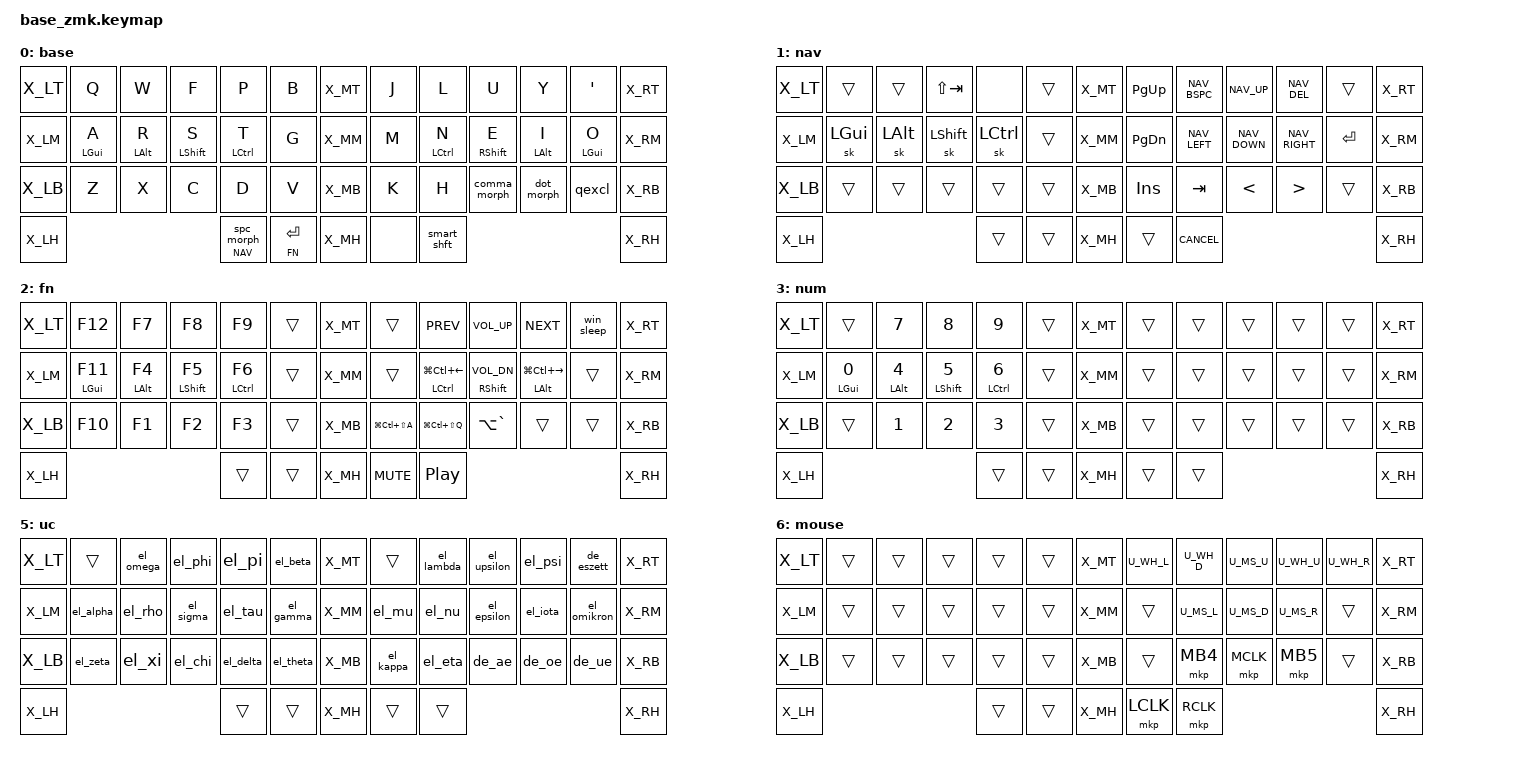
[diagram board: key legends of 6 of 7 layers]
#include <behaviors.dtsi>
#include <behaviors/num_word.dtsi> // requires auto-layer module
#include <dt-bindings/zmk/keys.h>
#if CONFIG_WIRELESS
    #include <dt-bindings/zmk/bt.h>
    #define _BT_SEL_KEYS_ &bt BT_SEL 0 &bt BT_SEL 1 &bt BT_SEL 2 &bt BT_SEL 3 &bt BT_CLR
#else
    #define _BT_SEL_KEYS_ &trans &trans &trans &trans &trans
#endif

#include "zmk-helpers/helper.h"
#include "zmk-helpers/unicode-chars/greek.dtsi"
#include "zmk-helpers/unicode-chars/german.dtsi"

#define DEF 0
#define NAV 1
#define FN 2
#define NUM 3
#define SYS 4
#define UC 5
#define MOUSE 6

#include "combos.dtsi"  // requires layer aliases
#include "mouse.dtsi"
#include "extra_keys.h"

#define XXX &none
#define ___ &trans

/* Global settings */

#define QUICK_TAP_MS 175

&sk {  // sticky-key config
    release-after-ms = <900>;  // release after 0.6s
    quick-release;             // no double capitalization when rolling keys
};

&sl {  // sticky-layer config
    ignore-modifiers;          // allow chording sticky mods & layers
};

&lt {  // layer-tap config
    flavor = "balanced";
    tapping-term-ms = <200>;
    quick-tap-ms = <QUICK_TAP_MS>;
};

/* Homerow mods */

#define KEYS_L LT0 LT1 LT2 LT3 LT4 LM0 LM1 LM2 LM3 LM4 LB0 LB1 LB2 LB3 LB4  // left hand
#define KEYS_R RT0 RT1 RT2 RT3 RT4 RM0 RM1 RM2 RM3 RM4 RB0 RB1 RB2 RB3 RB4  // right hand
#define THUMBS LH1 LH0 RH0 RH1                                      // thumbs

/ {
    behaviors {
        /* Homerow mods */

        hml: homerow_mods_left {
            compatible = "zmk,behavior-hold-tap";
            label = "HOMEROW_MODS_LEFT";
            #binding-cells = <2>;
            flavor = "balanced";
            tapping-term-ms = <280>;
            quick-tap-ms = <QUICK_TAP_MS>;
            require-prior-idle-ms = <150>;
            bindings = <&kp>, <&kp>;
            hold-trigger-key-positions = <KEYS_R THUMBS>;  // right-hand keys and thumbs
            hold-trigger-on-release;
        };

        hmr: homerow_mods_right {
            compatible = "zmk,behavior-hold-tap";
            label = "HOMEROW_MODS_RIGHT";
            #binding-cells = <2>;
            flavor = "balanced";
            tapping-term-ms = <280>;
            quick-tap-ms = <QUICK_TAP_MS>;
            require-prior-idle-ms = <150>;
            bindings = <&kp>, <&kp>;
            hold-trigger-key-positions = <KEYS_L THUMBS>;  // left-hand keys and thumbs
            hold-trigger-on-release;
        };

        // used for HRM-combo
        hml_repeat: homerow_mods_left_repeat {
            compatible = "zmk,behavior-hold-tap";
            label = "HOMEROW_MODS_LEFT_REPEAT";
            #binding-cells = <2>;
            flavor = "balanced";
            tapping-term-ms = <280>;
            quick-tap-ms = <QUICK_TAP_MS>;
            require-prior-idle-ms = <150>;
            bindings = <&kp>, <&key_repeat>;
            hold-trigger-key-positions = <KEYS_R THUMBS>;
            hold-trigger-on-release;
        };

        hmr_lpar_lt: homerow_mods_right_lpar_lt {
            compatible = "zmk,behavior-hold-tap";
            label = "HOMEROW_MODS_RIGHT_LPAR_LT";
            #binding-cells = <2>;
            flavor = "balanced";
            tapping-term-ms = <280>;
            quick-tap-ms = <QUICK_TAP_MS>;
            require-prior-idle-ms = <150>;
            bindings = <&kp>, <&lpar_lt>;
            hold-trigger-key-positions = <KEYS_L THUMBS>;
            hold-trigger-on-release;
        };

        hmr_rpar_gt: homerow_mods_right_rpar_gt {
            compatible = "zmk,behavior-hold-tap";
            label = "HOMEROW_MODS_RIGHT_RPAR_GT";
            #binding-cells = <2>;
            flavor = "balanced";
            tapping-term-ms = <280>;
            quick-tap-ms = <QUICK_TAP_MS>;
            require-prior-idle-ms = <150>;
            bindings = <&kp>, <&rpar_gt>;
            hold-trigger-key-positions = <KEYS_L THUMBS>;
            hold-trigger-on-release;
        };

        /* Nav cluster */

        // long-tap action on hold, short-tap action on all interrupts
        mt: mod_tap {
            compatible = "zmk,behavior-hold-tap";
            #binding-cells = <2>;
            flavor = "tap-preferred";
            tapping-term-ms = <220>;
            quick-tap-ms = <220>;
            hold-trigger-key-positions = <0>;
            bindings = <&kp>, <&kp>;
        };

        mt_home: mod_tap_home {
            compatible = "zmk,behavior-hold-tap";
            #binding-cells = <2>;
            flavor = "tap-preferred";
            tapping-term-ms = <220>;
            quick-tap-ms = <220>;
            hold-trigger-key-positions = <0>;
            bindings = <&masked_home>, <&kp>;
        };

        mt_end: mod_tap_end {
            compatible = "zmk,behavior-hold-tap";
            #binding-cells = <2>;
            flavor = "tap-preferred";
            tapping-term-ms = <220>;
            quick-tap-ms = <220>;
            hold-trigger-key-positions = <0>;
            bindings = <&masked_end>, <&kp>;
        };

        // mask CTRL when holding left/right to avoid accidental jumps to beginning/end of document
        masked_home: masked_home {
            compatible = "zmk,behavior-mod-morph";
            #binding-cells = <0>;
            bindings = <&kp HOME>, <&kp HOME>;
            mods = <(MOD_LCTL)>;
        };

        masked_end: masked_end {
            compatible = "zmk,behavior-mod-morph";
            #binding-cells = <0>;
            bindings = <&kp END>, <&kp END>;
            mods = <(MOD_LCTL)>;
        };

        /* Caps-word, num-word and smart-mouse */

        // tap: sticky-shift | shift + tap/ double-tap: caps-word | hold: shift
        smart_shft: smart_shift {
            compatible = "zmk,behavior-mod-morph";
            #binding-cells = <0>;
            bindings = <&sk LSHFT>, <&caps_word>;
            mods = <(MOD_LSFT)>;
        };

        // tap: num-word | double-tap: sticky num-layer | hold: num-layer
        smart_num: smart_num {
            compatible = "zmk,behavior-hold-tap";
            label = "SMART_NUM";
            #binding-cells = <2>;
            flavor = "balanced";
            tapping-term-ms = <200>;
            quick-tap-ms = <QUICK_TAP_MS>;
            bindings = <&mo>, <&num_dance>;
        };

        num_dance: num_word_dance {
            compatible = "zmk,behavior-tap-dance";
            label = "NUM_WORD_DANCE";
            #binding-cells = <0>;
            tapping-term-ms = <200>;
            bindings = <&num_word NUM>, <&sl NUM>;
        };

        // smart-mouse, requires PR #1366
        smart_mouse: smart_mouse {
            compatible = "zmk,behavior-tri-state";
            label = "SMART_MOUSE";
            #binding-cells = <0>;
            bindings = <&tog MOUSE>, <&none>, <&tog MOUSE>;
            ignored-key-positions = <LT1 LT3 RT0 RT1 RT2 RT3 RT4 RM1 RM2 RM3 RB1 RB2 RB3 RH0 RH1>;
            ignored-layers = <MOUSE>;
        };

        /* Custom behaviors */

        // Alt+Tab swapper, requires PR #1366
        swapper: swapper {
            compatible = "zmk,behavior-tri-state";
            label = "SWAPPER";
            #binding-cells = <0>;
            bindings = <&kt LALT>, <&kp TAB>, <&kt LALT>;
            ignored-key-positions = <LT2>;
        };

        // Sticky layer + sticky shift (workaround for issue #1421)
        sls: sticky_layer_shift {
            compatible = "zmk,behavior-sticky-key";
            label = "STICKY_LAYER_SHIFT";
            #binding-cells = <1>;
            release-after-ms = <1000>;
            bindings = <&uc_shift>;
            ignore-modifiers;
        };

        // tap: comma | shift + tap: semicolon | ctrl + shift + tap: <
        comma_morph: comma_morph {
            compatible = "zmk,behavior-mod-morph";
            label = "COMMA_MORPH";
            #binding-cells = <0>;
            bindings = <&kp COMMA>, <&comma_inner_morph>;
            mods = <(MOD_LSFT|MOD_RSFT)>;
        };

        comma_inner_morph: comma_inner_morph {
            compatible = "zmk,behavior-mod-morph";
            label = "COMMA_INNER_MORPH";
            #binding-cells = <0>;
            bindings = <&kp SEMICOLON>, <&kp LESS_THAN>;
            mods = <(MOD_LCTL|MOD_RCTL)>;
        };

        // tap: dot | shift + tap: colon | ctrl + shift + tap: >
        dot_morph: dot_morph {
            compatible = "zmk,behavior-mod-morph";
            label = "DOT_MORPH";
            #binding-cells = <0>;
            bindings = <&kp DOT>, <&dot_inner_morph>;
            mods = <(MOD_LSFT|MOD_RSFT)>;
        };

        dot_inner_morph: dot_inner_morph {
            compatible = "zmk,behavior-mod-morph";
            label = "DOT_INNER_MORPH";
            #binding-cells = <0>;
            bindings = <&kp COLON>, <&kp GREATER_THAN>;
            mods = <(MOD_LCTL|MOD_RCTL)>;
        };

        // tap: qmark | shift + tap: excl
        qexcl: question_exclamation {
            compatible = "zmk,behavior-mod-morph";
            label = "QUESTION_EXCLAMATION";
            #binding-cells = <0>;
            bindings = <&kp QMARK>, <&kp EXCL>;
            mods = <(MOD_LSFT|MOD_RSFT)>;
        };

        // tap: left/right parenthesis | shft + tap: less-than/greater-than
        lpar_lt: left_parenthesis_less_than {
            compatible = "zmk,behavior-mod-morph";
            label = "LEFT_PARENTHESIS_LESS_THAN";
            #binding-cells = <0>;
            bindings = <&kp LPAR>, <&kp LT>;
            mods = <(MOD_LSFT|MOD_RSFT)>;
        };

        rpar_gt: right_parenthesis_greater_than {
            compatible = "zmk,behavior-mod-morph";
            label = "RIGHT_PARENTHESIS_GREATER_THAN";
            #binding-cells = <0>;
            bindings = <&kp RPAR>, <&kp GT>;
            mods = <(MOD_LSFT|MOD_RSFT)>;
        };

        // tap: space | shift + tap: dot -> space -> sticky shift | hold: activate layer
        lt_spc: layer_tap_space {
            compatible = "zmk,behavior-hold-tap";
            label = "LAYER_TAP_SPACE";
            #binding-cells = <2>;
            flavor = "balanced";
            tapping-term-ms = <200>;
            quick-tap-ms = <QUICK_TAP_MS>;
            bindings = <&mo>, <&spc_morph>;
        };

        spc_morph: space_morph {
            compatible = "zmk,behavior-mod-morph";
            label = "SPACE_MORPH";
            #binding-cells = <0>;
            bindings = <&kp SPACE>, <&dot_spc>;
            mods = <(MOD_LSFT|MOD_RSFT)>;
        };

        // tap: backspace | lshft + tap: delete | rshft + tap: shift-delete
        bs_del: backspace_delete {
            compatible = "zmk,behavior-mod-morph";
            label = "BACKSPACE_DELETE";
            #binding-cells = <0>;
            bindings = <&kp BSPC>, <&kp DEL>;
            mods = <(MOD_LSFT|MOD_RSFT)>;
            keep-mods = <MOD_RSFT>;
        };

        // tap: copy | double-tap: cut
        copy_cut: copy_cut {
            compatible = "zmk,behavior-tap-dance";
            label = "COPY_CUT";
            #binding-cells = <0>;
            tapping-term-ms = <200>;
            bindings = <&kp LC(INS)>, <&kp LC(X)>;
        };
    };

    macros {
        // Sticky layer + sticky shift (workaround for issue #1421)
        uc_shift: unicode_shift {
            compatible = "zmk,behavior-macro";
            label = "UNICODE_SHIFT";
            #binding-cells = <0>;
            wait-ms = <0>;
            tap-ms = <1>;
            bindings = <&macro_press &mo UC &kp LSHFT>,
                       <&macro_pause_for_release>,
                       <&macro_release &mo UC &kp LSHFT>;
        };

        // tap: space | shift + tap: dot -> space -> sticky shift | hold: activate layer
        dot_spc: dot_space {
            compatible = "zmk,behavior-macro";
            label = "DOT_SPACE";
            #binding-cells = <0>;
            wait-ms = <0>;
            tap-ms = <5>;
            bindings = <&kp DOT &kp SPACE &sk LSHFT>;
        };

        // Windows sleep key
        win_sleep: windows_sleep {
            compatible = "zmk,behavior-macro";
            label = "WINDOWS_SLEEP";
            #binding-cells = <0>;
            wait-ms = <500>;
            tap-ms = <50>;
            bindings = <&kp LG(X) &kp U &kp S>;
        };
    };
};

// misc aliases
#define CANCEL      &kp K_CANCEL             // cancel caps-word, num-word and smart-mouse
#define DSK_PREV    &hmr LCTRL LG(LC(LEFT))   // previous desktop
#define DSK_NEXT    &hmr LALT LG(LC(RIGHT)) // next     desktop
#define PIN_WIN     &kp LG(LC(LS(Q)))        // pin window across desktops
#define PIN_APP     &kp LG(LC(LS(A)))        // pin application across desktops
#define DSK_MGR     &kp LA(GRAVE)            // desktop manager
#define VOL_DOWN    &hmr RSHFT C_VOL_DN

/* Keymap */

// ZMK_CONDITIONAL_LAYER(sys, FN NUM, SYS)  // FN + NUM --> SYS

ZMK_LAYER(base,
//╭──────╮ ╭─────────────┬─────────────┬─────────────┬─────────────┬─────────────╮ ╭──────╮ ╭─────────────┬─────────────┬─────────────┬─────────────┬─────────────╮ ╭──────╮
    X_LT     &kp Q         &kp W         &kp F         &kp P         &kp B           X_MT     &kp J         &kp L         &kp U         &kp Y         &kp SQT         X_RT
//├──────┤ ├─────────────┼─────────────┼─────────────┼─────────────┼─────────────┤ ├──────┤ ├─────────────┼─────────────┼─────────────┼─────────────┼─────────────┤ ├──────┤
    X_LM     &hml LGUI A   &hml LALT R   &hml LSHFT S  &hml LCTRL T  &kp G           X_MM     &kp M         &hmr LCTRL N  &hmr RSHFT E  &hmr LALT I   &hmr LGUI O     X_RM
//├──────┤ ├─────────────┼─────────────┼─────────────┼─────────────┼─────────────┤ ├──────┤ ├─────────────┼─────────────┼─────────────┼─────────────┼─────────────┤ ├──────┤
    X_LB     &kp Z         &kp X         &kp C         &kp D         &kp V           X_MB     &kp K         &kp H         &comma_morph  &dot_morph    &qexcl          X_RB
//├──────┤ ╰─────────────┼─────────────┴─────────────┼─────────────┼─────────────┤ ├──────┤ ├─────────────┼─────────────┼─────────────┴───────────────────────────╯ ├──────┤
    X_LH                                               &lt_spc NAV 0 &lt FN RET      X_MH     &none     &smart_shft                                               X_RH
//╰──────╯                                           ╰─────────────┴─────────────╯ ╰──────╯ ╰─────────────┴─────────────╯                                           ╰──────╯
)

ZMK_LAYER(nav,
//╭──────╮ ╭─────────────┬─────────────┬─────────────┬─────────────┬─────────────╮ ╭──────╮ ╭─────────────┬─────────────┬─────────────┬─────────────┬─────────────╮ ╭──────╮
    X_LT     ___           ___           &kp LS(TAB)   &none         ___             X_MT     &kp PG_UP     NAV_BSPC      NAV_UP        NAV_DEL       ___             X_RT
//├──────┤ ├─────────────┼─────────────┼─────────────┼─────────────┼─────────────┤ ├──────┤ ├─────────────┼─────────────┼─────────────┼─────────────┼─────────────┤ ├──────┤
    X_LM     &sk LGUI      &sk LALT      &sk LSHFT     &sk LCTRL     ___             X_MM     &kp PG_DN     NAV_LEFT      NAV_DOWN      NAV_RIGHT     &kp RET         X_RM
//├──────┤ ├─────────────┼─────────────┼─────────────┼─────────────┼─────────────┤ ├──────┤ ├─────────────┼─────────────┼─────────────┼─────────────┼─────────────┤ ├──────┤
    X_LB     ___           ___           ___           ___           ___             X_MB     &kp INS       &kp TAB       &kp LT        &kp GT        ___             X_RB
//├──────┤ ╰─────────────┼─────────────┴─────────────┼─────────────┼─────────────┤ ├──────┤ ├─────────────┼─────────────┼─────────────┴───────────────────────────╯ ├──────┤
    X_LH                                               ___           ___             X_MH     ___           CANCEL                                                    X_RH
//╰──────╯                                           ╰─────────────┴─────────────╯ ╰──────╯ ╰─────────────┴─────────────╯                                           ╰──────╯
)

ZMK_LAYER(fn,
//╭──────╮ ╭─────────────┬─────────────┬─────────────┬─────────────┬─────────────╮ ╭──────╮ ╭─────────────┬─────────────┬─────────────┬─────────────┬─────────────╮ ╭──────╮
    X_LT     &kp F12       &kp F7        &kp F8        &kp F9        ___             X_MT     ___           &kp C_PREV    &kp C_VOL_UP  &kp C_NEXT    &win_sleep      X_RT
//├──────┤ ├─────────────┼─────────────┼─────────────┼─────────────┼─────────────┤ ├──────┤ ├─────────────┼─────────────┼─────────────┼─────────────┼─────────────┤ ├──────┤
    X_LM     &hml LGUI F11 &hml LALT F4  &hml LSHFT F5 &hml LCTRL F6 ___             X_MM     ___           DSK_PREV      VOL_DOWN      DSK_NEXT      ___             X_RM
//├──────┤ ├─────────────┼─────────────┼─────────────┼─────────────┼─────────────┤ ├──────┤ ├─────────────┼─────────────┼─────────────┼─────────────┼─────────────┤ ├──────┤
    X_LB     &kp F10       &kp F1        &kp F2        &kp F3        ___             X_MB     PIN_APP       PIN_WIN       DSK_MGR       ___           ___             X_RB
//├──────┤ ╰─────────────┼─────────────┴─────────────┼─────────────┼─────────────┤ ├──────┤ ├─────────────┼─────────────┼─────────────┴───────────────────────────╯ ├──────┤
    X_LH                                               ___           ___             X_MH     &kp C_MUTE    &kp C_PP                                                  X_RH
//╰──────╯                                           ╰─────────────┴─────────────╯ ╰──────╯ ╰─────────────┴─────────────╯                                           ╰──────╯
)

ZMK_LAYER(num,
//╭──────╮ ╭─────────────┬─────────────┬─────────────┬─────────────┬─────────────╮ ╭──────╮ ╭─────────────┬─────────────┬─────────────┬─────────────┬─────────────╮ ╭──────╮
    X_LT     ___           &kp N7        &kp N8        &kp N9        ___             X_MT     ___           ___           ___           ___           ___             X_RT
//├──────┤ ├─────────────┼─────────────┼─────────────┼─────────────┼─────────────┤ ├──────┤ ├─────────────┼─────────────┼─────────────┼─────────────┼─────────────┤ ├──────┤
    X_LM     &hml LGUI N0  &hml LALT N4  &hml LSHFT N5 &hml LCTRL N6 ___             X_MM     ___           ___           ___           ___           ___             X_RM
//├──────┤ ├─────────────┼─────────────┼─────────────┼─────────────┼─────────────┤ ├──────┤ ├─────────────┼─────────────┼─────────────┼─────────────┼─────────────┤ ├──────┤
    X_LB     ___           &kp N1        &kp N2        &kp N3        ___             X_MB     ___           ___           ___           ___           ___             X_RB
//├──────┤ ╰─────────────┼─────────────┴─────────────┼─────────────┼─────────────┤ ├──────┤ ├─────────────┼─────────────┼─────────────┴───────────────────────────╯ ├──────┤
    X_LH                                               ___           ___             X_MH     ___           ___                                                       X_RH
//╰──────╯                                           ╰─────────────┴─────────────╯ ╰──────╯ ╰─────────────┴─────────────╯                                           ╰──────╯
)

ZMK_LAYER(sys,
//╭──────╮ ╭─────────────┬─────────────┬─────────────┬─────────────┬─────────────╮ ╭──────╮ ╭─────────────┬─────────────┬─────────────┬─────────────┬─────────────╮ ╭──────╮
    X_LT                                _BT_SEL_KEYS_                                X_MT     ___           ___           ___           ___           ___             X_RT
//├──────┤ ├─────────────┼─────────────┼─────────────┼─────────────┼─────────────┤ ├──────┤ ├─────────────┼─────────────┼─────────────┼─────────────┼─────────────┤ ├──────┤
    X_LM     ___           ___           ___           ___           &bootloader     X_MM     &bootloader   ___           ___           ___           ___             X_RM
//├──────┤ ├─────────────┼─────────────┼─────────────┼─────────────┼─────────────┤ ├──────┤ ├─────────────┼─────────────┼─────────────┼─────────────┼─────────────┤ ├──────┤
    X_LB     ___           ___           ___           ___           &sys_reset      X_MB     &sys_reset    ___           ___           ___           ___             X_RB
//├──────┤ ╰─────────────┼─────────────┴─────────────┼─────────────┼─────────────┤ ├──────┤ ├─────────────┼─────────────┼─────────────┴───────────────────────────╯ ├──────┤
    X_LH                                               ___           ___             X_MH     ___           ___                                                       X_RH
//╰──────╯                                           ╰─────────────┴─────────────╯ ╰──────╯ ╰─────────────┴─────────────╯                                           ╰──────╯
)

ZMK_LAYER(uc,
//╭──────╮ ╭─────────────┬─────────────┬─────────────┬─────────────┬─────────────╮ ╭──────╮ ╭─────────────┬─────────────┬─────────────┬─────────────┬─────────────╮ ╭──────╮
    X_LT     ___           &el_omega     &el_phi       &el_pi        &el_beta        X_MT     ___           &el_lambda    &el_upsilon   &el_psi       &de_eszett      X_RT
//├──────┤ ├─────────────┼─────────────┼─────────────┼─────────────┼─────────────┤ ├──────┤ ├─────────────┼─────────────┼─────────────┼─────────────┼─────────────┤ ├──────┤
    X_LM     &el_alpha     &el_rho       &el_sigma     &el_tau       &el_gamma       X_MM     &el_mu        &el_nu        &el_epsilon   &el_iota      &el_omikron     X_RM
//├──────┤ ├─────────────┼─────────────┼─────────────┼─────────────┼─────────────┤ ├──────┤ ├─────────────┼─────────────┼─────────────┼─────────────┼─────────────┤ ├──────┤
    X_LB     &el_zeta      &el_xi        &el_chi       &el_delta     &el_theta       X_MB     &el_kappa     &el_eta       &de_ae        &de_oe        &de_ue          X_RB
//├──────┤ ╰─────────────┼─────────────┴─────────────┼─────────────┼─────────────┤ ├──────┤ ├─────────────┼─────────────┼─────────────┴───────────────────────────╯ ├──────┤
    X_LH                                               ___           ___             X_MH     ___           ___                                                       X_RH
//╰──────╯                                           ╰─────────────┴─────────────╯ ╰──────╯ ╰───────────────────────────╯                                           ╰──────╯
)

ZMK_LAYER(mouse,
//╭──────╮ ╭─────────────┬─────────────┬─────────────┬─────────────┬─────────────╮ ╭──────╮ ╭─────────────┬─────────────┬─────────────┬─────────────┬─────────────╮ ╭──────╮
    X_LT     ___           ___           ___           ___           ___             X_MT     U_WH_L        U_WH_D        U_MS_U         U_WH_U       U_WH_R          X_RT
//├──────┤ ├─────────────┼─────────────┼─────────────┼─────────────┼─────────────┤ ├──────┤ ├─────────────┼─────────────┼─────────────┼─────────────┼─────────────┤ ├──────┤
    X_LM     ___           ___           ___           ___           ___             X_MM     ___           U_MS_L        U_MS_D         U_MS_R       ___             X_RM
//├──────┤ ├─────────────┼─────────────┼─────────────┼─────────────┼─────────────┤ ├──────┤ ├─────────────┼─────────────┼─────────────┼─────────────┼─────────────┤ ├──────┤
    X_LB     ___           ___           ___           ___           ___             X_MB     ___           &mkp MB4      &mkp MCLK      &mkp MB5     ___             X_RB
//├──────┤ ╰─────────────┼─────────────┴─────────────┼─────────────┼─────────────┤ ├──────┤ ├─────────────┼─────────────┼─────────────┴───────────────────────────╯ ├──────┤
    X_LH                                               ___           ___             X_MH     &mkp LCLK     &mkp RCLK                                                 X_RH
//╰──────╯                                           ╰─────────────┴─────────────╯ ╰──────╯ ╰─────────────┴─────────────╯                                           ╰──────╯
)

/* vim: set ft=c tw=174: */
